AUTOSAR XML (schema 4-2-1)
standard types defined: dtRef_const_VOID, dtRef_VOID, boolean, float32, float64, sint16, sint16_least, sint32, sint32_least, sint64, sint8, sint8_least, uint16, uint16_least, uint32, uint32_least, uint64, uint8, uint8_least, boolean_CompuMethod, boolean_DataConstr, float32_DataConstr, float64_DataConstr, sint16_DataConstr, sint16_least_DataConstr, sint32_DataConstr, sint32_least_DataConstr, sint64_DataConstr, sint8_DataConstr, sint8_least_DataConstr, uint16_DataConstr, uint16_least_DataConstr, uint32_DataConstr, uint32_least_DataConstr, uint64_DataConstr, uint8_DataConstr, uint8_least_DataConstr
package /DataTypes/BaseTypes
  base type uint4: base-type-size=4, native-declaration=uint8, category=FIXED_LENGTH
  base type uint1: base-type-size=1, native-declaration=uint8, category=FIXED_LENGTH
package /DataTypes/ImplementationDataTypes
  impl type uint4: category=VALUE, base-type=uint4
  impl type boolean1: category=VALUE, base-type=uint1
package /PortInterfaces
  4 x sender receiver interface:
    CmdControl
      5 x data, all with type=uint8:
        LedCmd
        TargetMode
        Cmd_AliveCnt
        PwmDuty
        Cmd_Crc8
    EcuStatus
      5 x data:
        ECU_State: type=uint4
        ECU_AliveCnt: type=uint4
        Temperature: type=uint8
        SupplyVoltage: type=uint16
        FaultFlags: type=uint8
    FaultEvent
      data FaultCode: type=uint8
      data FaultActive: type=boolean1
    IoIf
      data LedState: type=boolean
      data PwmDuty: type=uint8
package /ComponentTypes
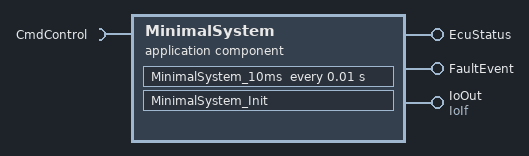
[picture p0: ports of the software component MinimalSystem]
  application sw component type MinimalSystem
    require port CmdControl: required-interface=CmdControl
      required-com-specs:
        data-element=LedCmd, init-value=0
        data-element=TargetMode, init-value=0
        data-element=Cmd_AliveCnt, init-value=0
        data-element=CmdControl/PwmDuty, init-value=0
        data-element=Cmd_Crc8, init-value=0
    provide port EcuStatus: provided-interface=EcuStatus
      provided-com-specs:
        data-element=ECU_State, init-value=0
        data-element=ECU_AliveCnt, init-value=0
        data-element=Temperature, init-value=0
        data-element=SupplyVoltage, init-value=0
        data-element=FaultFlags, init-value=0
    provide port FaultEvent: provided-com-specs=[{data-element=FaultCode, init-value=0}, {data-element=FaultActive, init-value=0}], provided-interface=FaultEvent
    provide port IoOut: provided-com-specs=[{data-element=LedState, init-value=0}, {data-element=IoIf/PwmDuty, init-value=0}], provided-interface=IoIf
    behavior MinimalSystem_IB
      init event MinimalSystem_Init_Ev: start-on-event=MinimalSystem_Init
      timing event MinimalSystem_10ms_Ev: start-on-event=MinimalSystem_10ms, offset=0, period=0.01
      runnable MinimalSystem_Init
      runnable MinimalSystem_10ms
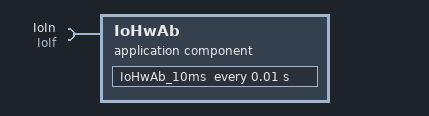
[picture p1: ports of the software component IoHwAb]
  application sw component type IoHwAb
    require port IoIn: required-com-specs=[{data-element=LedState, init-value=0}, {data-element=IoIf/PwmDuty, init-value=0}], required-interface=IoIf
    behavior IoHwAb_IB
      timing event IoHwAb_10ms_Ev: start-on-event=IoHwAb_10ms, offset=0, period=0.01
      runnable IoHwAb_10ms
